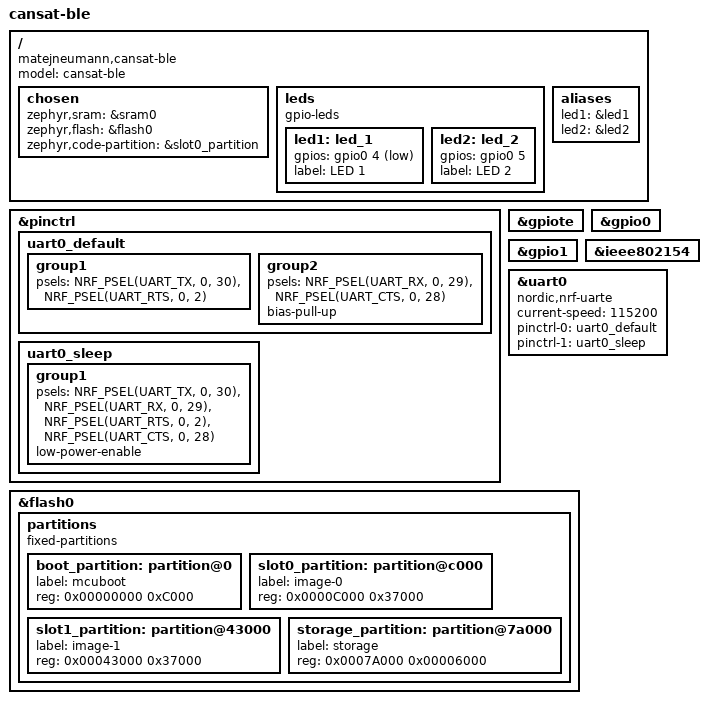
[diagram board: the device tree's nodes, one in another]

/dts-v1/;
#include <nordic/nrf52833_qdaa.dtsi>

/ {
	model = "cansat-ble";
	compatible = "matejneumann,cansat-ble";
    chosen {
        zephyr,sram = &sram0;
        zephyr,flash = &flash0;
        zephyr,code-partition = &slot0_partition;
    };

    leds {
        compatible = "gpio-leds";
        status = "okay";
        led1: led_1 {
            gpios = <&gpio0 4 GPIO_ACTIVE_LOW>;
            label = "LED 1";
        };
        led2: led_2 {
            gpios = <&gpio0 5 GPIO_ACTIVE_HIGH>;
            label = "LED 2";
        };
    };

    aliases {
        led1 = &led1;
        led2 = &led2;
//        watchdog0 = &wdt0;
    };

};

&pinctrl {
    uart0_default: uart0_default {
        group1 {
            psels = <NRF_PSEL(UART_TX, 0, 30)>,
                    <NRF_PSEL(UART_RTS, 0, 2)>;
        };
        group2 {
            psels = <NRF_PSEL(UART_RX, 0, 29)>,
                    <NRF_PSEL(UART_CTS, 0, 28)>;
                    bias-pull-up;
        };
    };

    uart0_sleep: uart0_sleep {
        group1 {
            psels = <NRF_PSEL(UART_TX, 0, 30)>,
                    <NRF_PSEL(UART_RX, 0, 29)>,
                    <NRF_PSEL(UART_RTS, 0, 2)>,
                    <NRF_PSEL(UART_CTS, 0, 28)>;
                    low-power-enable;
        };
    };
};

&gpiote {
    status = "okay";
};

&gpio0 {
    status = "okay";
};

&gpio1 {
    status = "okay";
};

&ieee802154 {
    status = "okay";
};

&uart0 {
    compatible = "nordic,nrf-uarte";
    status = "okay";
    current-speed = <115200>;
    pinctrl-0 = <&uart0_default>;
    pinctrl-1 = <&uart0_sleep>;
    pinctrl-names = "default", "sleep";
};


&flash0 {
    partitions {
        compatible = "fixed-partitions";
        #address-cells = <1>;
        #size-cells = <1>;

        boot_partition: partition@0 {
            label = "mcuboot";
            reg = <0x00000000 0xC000>;
        };
        slot0_partition: partition@c000 {
            label = "image-0";
            reg = <0x0000C000 0x37000>;
        };
        slot1_partition: partition@43000 {
            label = "image-1";
            reg = <0x00043000 0x37000>;
        };
        storage_partition: partition@7a000 {
            label = "storage";
            reg = <0x0007A000 0x00006000>;
        };
    };
};


